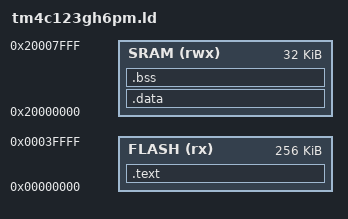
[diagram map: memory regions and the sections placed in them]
MEMORY
{
    FLASH (rx)  : ORIGIN = 0x00000000, LENGTH = 256K
    SRAM  (rwx) : ORIGIN = 0x20000000, LENGTH = 32K
}

_estack = ORIGIN(SRAM) + LENGTH(SRAM);

SECTIONS
{
    .text :
    {
        KEEP(*(.isr_vector))
        *(.text*)
        *(.rodata*)
        . = ALIGN(4);
        _etext = .;
    } > FLASH

    .data : AT(_etext)
    {
        . = ALIGN(4);
        _sdata = .;
        *(.data*)
        . = ALIGN(4);
        _edata = .;
    } > SRAM

    .bss :
    {
        . = ALIGN(4);
        _sbss = .;
        *(.bss*)
        *(COMMON)
        . = ALIGN(4);
        _ebss = .;
    } > SRAM
}
